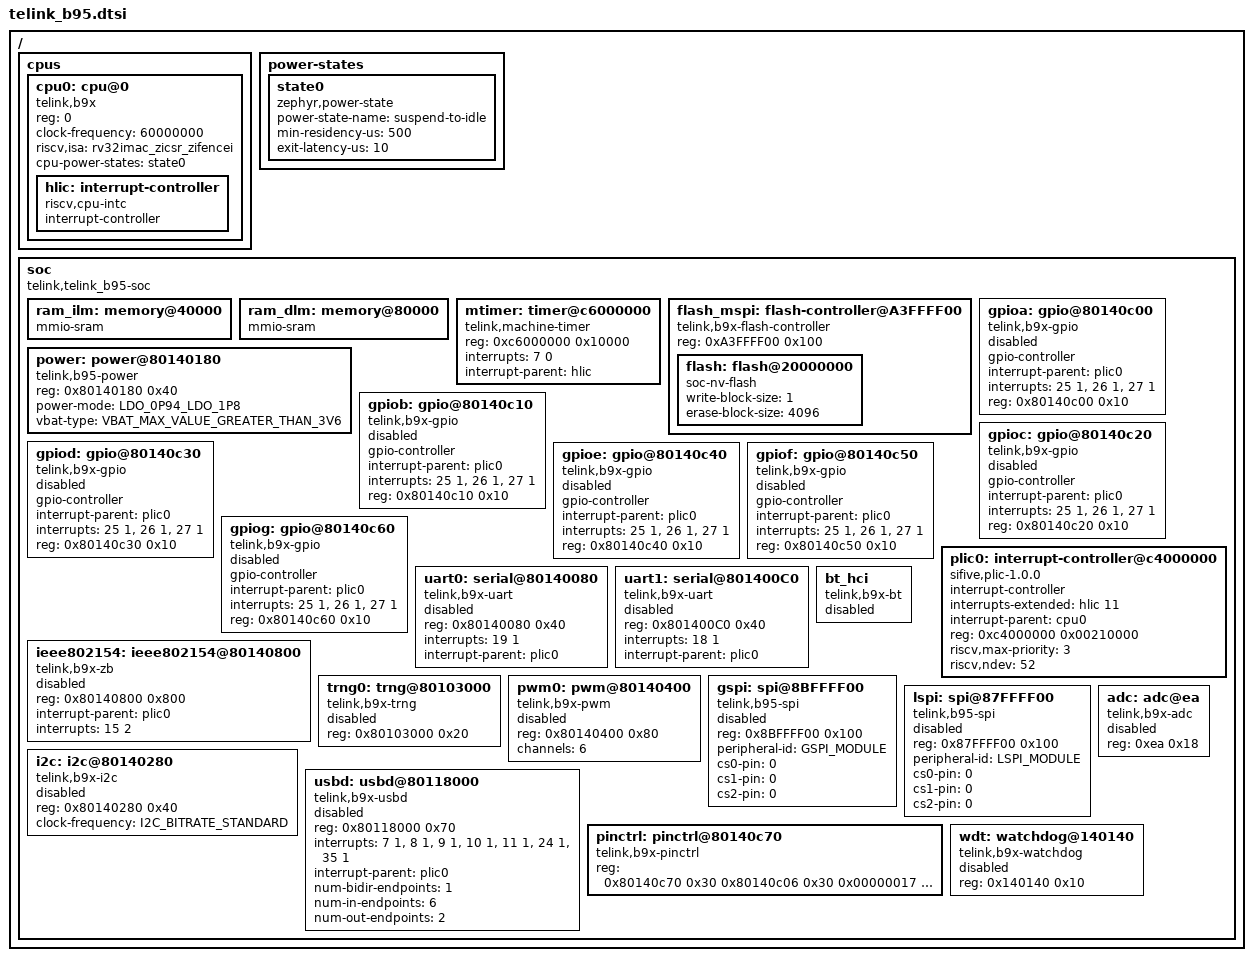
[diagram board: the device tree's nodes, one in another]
/*
 * Copyright (c) 2024 Telink Semiconductor
 *
 * SPDX-License-Identifier: Apache-2.0
 */

/dts-v1/;

#include <zephyr/dt-bindings/adc/adc.h>
#include <zephyr/dt-bindings/adc/b9x-adc.h>
#include <zephyr/dt-bindings/gpio/gpio.h>
#include <zephyr/dt-bindings/i2c/i2c.h>
#include <zephyr/dt-bindings/pwm/pwm.h>

/ {
	#address-cells = <1>;
	#size-cells = <1>;

	cpus {
		#address-cells = <1>;
		#size-cells = <0>;
		cpu0: cpu@0 {
			reg = <0>;
			clock-frequency = <60000000>;
			riscv,isa = "rv32imac_zicsr_zifencei";
			compatible ="telink,b9x", "riscv";
			hlic: interrupt-controller {
				compatible = "riscv,cpu-intc";
				#address-cells = <0>;
				#interrupt-cells = <1>;
				interrupt-controller;
			};
			cpu-power-states = <&state0>;
		};
	};

	power-states {
		state0: state0 {
			compatible = "zephyr,power-state";
			power-state-name = "suspend-to-idle";
			min-residency-us = <500>;
			exit-latency-us = <10>;
		};
	};

	soc {
		#address-cells = <1>;
		#size-cells = <1>;
		compatible = "telink,telink_b95-soc";
		ranges;

		ram_ilm: memory@40000 {
			compatible = "mmio-sram";
		};

		ram_dlm: memory@80000 {
			compatible = "mmio-sram";
		};

		mtimer: timer@c6000000 {
			compatible = "telink,machine-timer";
			reg = <0xc6000000 0x10000>;
			interrupts = <7 0>;
			interrupt-parent = <&hlic>;
		};

		flash_mspi: flash-controller@A3FFFF00 {
			compatible = "telink,b9x-flash-controller";
			reg = <0xA3FFFF00 0x100>;

			#address-cells = <1>;
			#size-cells = <1>;

			flash: flash@20000000 {
				compatible = "soc-nv-flash";
				write-block-size = <1>;
				erase-block-size = <4096>;
			};
		};

		power: power@80140180 {
			compatible = "telink,b95-power";
			reg = <0x80140180 0x40>;
			power-mode = "LDO_0P94_LDO_1P8";
			vbat-type = "VBAT_MAX_VALUE_GREATER_THAN_3V6";
			status = "okay";
		};

		gpioa: gpio@80140c00 {
			compatible = "telink,b9x-gpio";
			gpio-controller;
			interrupt-parent = <&plic0>;
			interrupts = <25 1>, <26 1>, <27 1>;
			reg = <0x80140c00 0x10>;
			status = "disabled";
			#gpio-cells = <2>;
		};

		gpiob: gpio@80140c10 {
			compatible = "telink,b9x-gpio";
			gpio-controller;
			interrupt-parent = <&plic0>;
			interrupts = <25 1>, <26 1>, <27 1>;
			reg = <0x80140c10 0x10>;
			status = "disabled";
			#gpio-cells = <2>;
		};

		gpioc: gpio@80140c20 {
			compatible = "telink,b9x-gpio";
			gpio-controller;
			interrupt-parent = <&plic0>;
			interrupts = <25 1>, <26 1>, <27 1>;
			reg = <0x80140c20 0x10>;
			status = "disabled";
			#gpio-cells = <2>;
		};

		gpiod: gpio@80140c30 {
			compatible = "telink,b9x-gpio";
			gpio-controller;
			interrupt-parent = <&plic0>;
			interrupts = <25 1>, <26 1>, <27 1>;
			reg = <0x80140c30 0x10>;
			status = "disabled";
			#gpio-cells = <2>;
		};

		gpioe: gpio@80140c40 {
			compatible = "telink,b9x-gpio";
			gpio-controller;
			interrupt-parent = <&plic0>;
			interrupts = <25 1>, <26 1>, <27 1>;
			reg = <0x80140c40 0x10>;
			status = "disabled";
			#gpio-cells = <2>;
		};

		gpiof: gpio@80140c50 {
			compatible = "telink,b9x-gpio";
			gpio-controller;
			interrupt-parent = <&plic0>;
			interrupts = <25 1>, <26 1>, <27 1>;
			reg = <0x80140c50 0x10>;
			status = "disabled";
			#gpio-cells = <2>;
		};

		gpiog: gpio@80140c60 {
			compatible = "telink,b9x-gpio";
			gpio-controller;
			interrupt-parent = <&plic0>;
			interrupts = <25 1>, <26 1>, <27 1>;
			reg = <0x80140c60 0x10>;
			status = "disabled";
			#gpio-cells = <2>;
		};

		plic0: interrupt-controller@c4000000 {
			compatible = "sifive,plic-1.0.0";
			#address-cells = <0>;
			#interrupt-cells = <2>;
			interrupt-controller;
			interrupts-extended = <&hlic 11>;
			interrupt-parent = <&cpu0>;
			reg = <0xc4000000 0x00210000>;
			riscv,max-priority = <3>;
			riscv,ndev = <52>;
		};

		uart0: serial@80140080 {
			compatible = "telink,b9x-uart";
			reg = <0x80140080 0x40>;
			interrupts = <19 1>;
			interrupt-parent = <&plic0>;
			status = "disabled";
		};

		uart1: serial@801400C0 {
			compatible = "telink,b9x-uart";
			reg = <0x801400C0 0x40>;
			interrupts = <18 1>;
			interrupt-parent = <&plic0>;
			status = "disabled";
		};

		ieee802154: ieee802154@80140800 {
			compatible = "telink,b9x-zb";
			reg = <0x80140800 0x800>;
			interrupt-parent = <&plic0>;
			interrupts = <15 2>;
			status = "disabled";
		};

		bt_hci: bt_hci {
			compatible = "telink,b9x-bt";
			status = "disabled";
		};

		trng0: trng@80103000 {
			compatible = "telink,b9x-trng";
			reg = <0x80103000 0x20>;
			status = "disabled";
		};

		pwm0: pwm@80140400 {
			compatible = "telink,b9x-pwm";
			reg = <0x80140400 0x80>;
			channels = <6>;
			status = "disabled";
			#pwm-cells = <3>;
		};

		gspi: spi@8BFFFF00 {
			compatible = "telink,b95-spi";
			reg = <0x8BFFFF00 0x100>;
			peripheral-id = "GSPI_MODULE";
			cs0-pin = "0";
			cs1-pin = "0";
			cs2-pin = "0";
			#address-cells = <1>;
			#size-cells = <0>;
			status = "disabled";
		};

		lspi: spi@87FFFF00 {
			compatible = "telink,b95-spi";
			reg = <0x87FFFF00 0x100>;
			peripheral-id = "LSPI_MODULE";
			cs0-pin = "0";
			cs1-pin = "0";
			cs2-pin = "0";
			#address-cells = <1>;
			#size-cells = <0>;
			status = "disabled";
		};

		i2c: i2c@80140280 {
			compatible = "telink,b9x-i2c";
			reg = <0x80140280 0x40>;
			#address-cells = <1>;
			#size-cells = <0>;
			status = "disabled";
			clock-frequency = <I2C_BITRATE_STANDARD>;
		};

		adc: adc@ea {
			compatible = "telink,b9x-adc";
			reg = <0xea 0x18>;
			status = "disabled";
			#io-channel-cells = <1>;
		};

		usbd: usbd@80118000 {
			compatible = "telink,b9x-usbd";
			reg = <0x80118000 0x70>;
			interrupts = <7 1>, <8 1>, <9 1>, <10 1>, <11 1>, <24 1>, <35 1>;
			interrupt-parent = <&plic0>;
			num-bidir-endpoints = <1>;
			num-in-endpoints = <6>;
			num-out-endpoints = <2>;
			status = "disabled";
		};

		pinctrl: pinctrl@80140c70 {
			compatible = "telink,b9x-pinctrl";
			reg = <0x80140c70 0x30
			       0x80140c06 0x30
			       0x00000017 0x0C>;
			reg-names = "pin_mux",
				    "gpio_en",
				    "pull_up_en";
			status = "okay";
		};

		wdt: watchdog@140140 {
			compatible = "telink,b9x-watchdog";
			reg = <0x140140 0x10>;
			status = "disabled";
		};
	};
};
